# STM32H730xxQ register map
File version: 1.0
Registers are 32-bit, read-write, reset 0x0 unless marked. A register's access mark holds for its fields unless they carry their own. Offsets are from the block's base; [hi:lo] are bit positions; {n}, {i} and the like mark numbered series; 'fields as' and 'values as' point back to an identical list.

## FMAC — Filter and Mathematical ACcelerator
Base 0x48024000
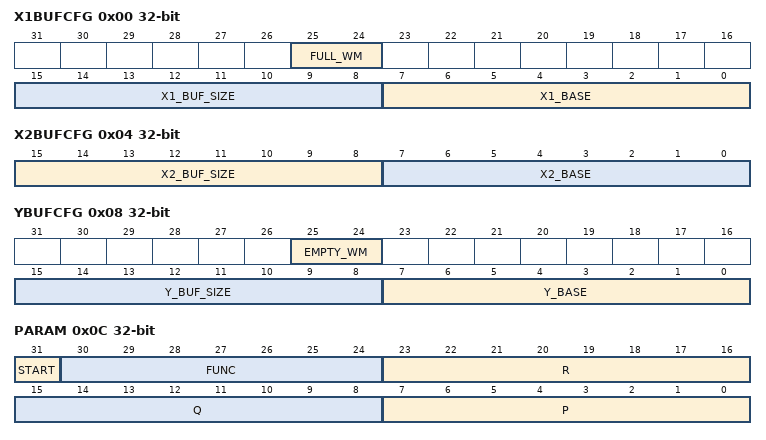
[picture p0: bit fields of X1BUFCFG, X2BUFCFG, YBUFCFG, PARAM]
0x00 X1BUFCFG — FMAC X1 Buffer Configuration register
  [25:24] FULL_WM — Watermark for buffer full flag
    0=WM_0_THRESHOLD_1; 1=WM_1_THRESHOLD_2; 2=WM_2_THRESHOLD_4; 3=WM_3_THRESHOLD_8
  [15:8] X1_BUF_SIZE — Allocated size of X1 buffer in 16-bit words
  [7:0] X1_BASE — Base address of X1 buffer
0x04 X2BUFCFG — FMAC X2 Buffer Configuration register
  [15:8] X2_BUF_SIZE — Size of X2 buffer in 16-bit words
  [7:0] X2_BASE — Base address of X2 buffer
0x08 YBUFCFG — FMAC Y Buffer Configuration register
  [25:24] EMPTY_WM — Watermark for buffer empty flag
    values as X1BUFCFG.FULL_WM
  [15:8] Y_BUF_SIZE — Size of Y buffer in 16-bit words
  [7:0] Y_BASE — Base address of Y buffer
0x0C PARAM — FMAC Parameter register
  [31] START — Enable execution
  [30:24] FUNC — Function
    1=LOAD_X1 (Load X1 buffer); 2=LOAD_X2 (Load X2 buffer); 3=LOAD_Y (Load Y buffer); 8=CONVO_FIR (Convolution (FIR filter)); 9=IIR_DIRECT_FORM_1 (IIR filter (direct form 1))
  [23:16] R — Input parameter R
  [15:8] Q — Input parameter Q
  [7:0] P — Input parameter P
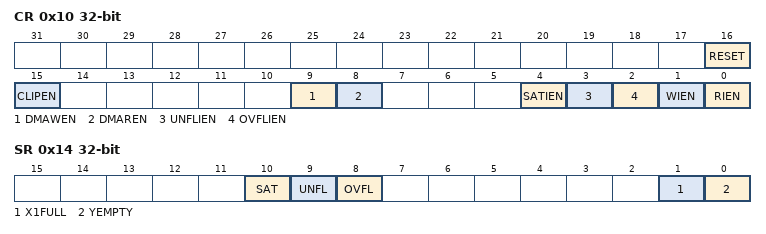
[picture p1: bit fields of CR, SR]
0x10 CR — FMAC Control register
  [16] RESET — Reset filter mathematical accelerator unit
  [15] CLIPEN — Enable clipping
  [9] DMAWEN — Enable DMA write channel requests
  [8] DMAREN — Enable DMA read channel requests
  [4] SATIEN — Enable saturation error interrupts
  [3] UNFLIEN — Enable underflow error interrupts
  [2] OVFLIEN — Enable overflow error interrupts
  [1] WIEN — Enable write interrupt
  [0] RIEN — Enable read interrupt
0x14 SR — FMAC Status register
  [10] SAT — Saturation error flag
  [9] UNFL — Underflow error flag
  [8] OVFL — Overflow error flag
  [1] X1FULL — X1 buffer full flag
  [0] YEMPTY — Y buffer empty flag
0x18 WDATA — FMAC Write Data register
  [15:0] WDATA — Write data
0x1C RDATA — FMAC Read Data register
  [15:0] RDATA — Read data

## CORDIC — COordincate Rotation DIgital Computer
Base 0x48024400
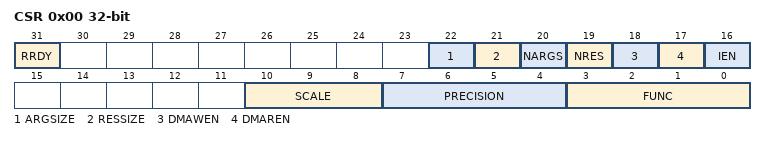
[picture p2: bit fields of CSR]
0x00 CSR — CORDIC control and status register
  [31] RRDY — Result Ready Flag
  [22] ARGSIZE — Width of input data
    0=INSIZE_32BITS (32 bits input data size (Q1.31 format)); 1=INSIZE_16BITS (16 bits input data size (Q1.15 format))
  [21] RESSIZE — Width of output data
    0=OUTSIZE_32BITS (32 bits output data size (Q1.31 format)); 1=OUTSIZE_16BITS (16 bits output data size (Q1.15 format))
  [20] NARGS — Number of arguments in RDATA register
    0=NBWRITE_1; 1=NBWRITE_2
  [19] NRES — Number of results in WDATA register
    0=NBREAD_1; 1=NBREAD_2
  [18] DMAWEN — DMA Write channel Enable
  [17] DMAREN — DMA Read channel Enable
  [16] IEN — Interrupt Enable
  [10:8] SCALE — Scaling factor
  [7:4] PRECISION
    1=PRECISION_1CYCLE; {v}=PRECISION_{v}CYCLES (v=2..15)
  [3:0] FUNC — Function
    0=COSINE; 1=SINE; 2=PHASE; 3=MODULUS; 4=ARCTANGENT; 5=HCOSINE (Hyperbolic Cosine); 6=HSINE (Hyperbolic Sine); 7=HARCTANGENT (Hyperbolic Arctangent); 8=NATURALLOG (Natural Logarithm); 9=SQUAREROOT
0x04 WDATA — CORDIC argument register
  [31:0] ARG — Input Argument
0x08 RDATA — CORDIC result register
  [31:0] RES — Output Result

## WWDG1 — Window WATCHDOG
Base 0x50003000
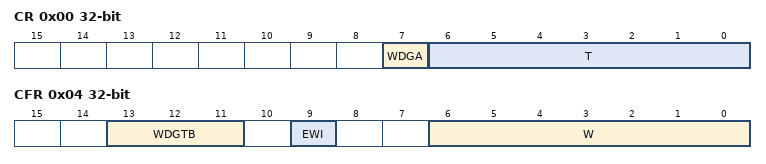
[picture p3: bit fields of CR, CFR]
0x00 CR — WWDG Control register
  [7] WDGA — Activation bit
  [6:0] T — T[6:0] bits (7-Bit counter (MSB to LSB))
0x04 CFR — WWDG Configuration register
  [13:11] WDGTB — WDGTB[2:0] bits (Timer Base)
    0=PRESCALER_1 (WWDG counter clock = (PCLK1/4096)/1); 1=PRESCALER_2 (WWDG counter clock = (PCLK1/4096)/2); 2=PRESCALER_4 (WWDG counter clock = (PCLK1/4096)/4); 3=PRESCALER_8 (WWDG counter clock = (PCLK1/4096)/8); 4=PRESCALER_16 (WWDG counter clock = (PCLK1/4096)/16); 5=PRESCALER_32 (WWDG counter clock = (PCLK1/4096)/32); 6=PRESCALER_64 (WWDG counter clock = (PCLK1/4096)/64); 7=PRESCALER_128 (WWDG counter clock = (PCLK1/4096)/128)
  [9] EWI — Early Wakeup Interrupt
  [6:0] W — W[6:0] bits (7-bit window value)
0x08 SR — WWDG Status register
  [0] EWIF — Early Wakeup Interrupt Flag
